# earlgrey register map
Vendor: lowRISC OpenTitan; File version: snapshot-20191101-1-518-g9293d546-dirty
CPU: RISCV 0, little endian, MPU, no FPU, 0 interrupt priority bits
Registers are 32-bit, read-write, reset 0x0 unless marked. A register's access mark holds for its fields unless they carry their own. Offsets are from the block's base; [hi:lo] are bit positions; lines under a group give offsets from that group; {n}, {i} and the like mark numbered series.

## hmac
Base 0x40120000
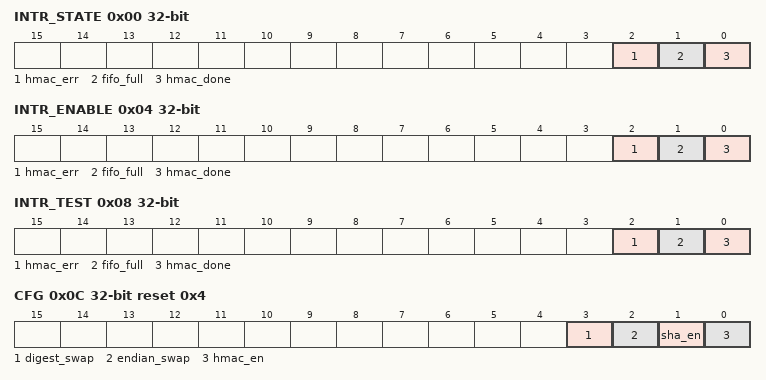
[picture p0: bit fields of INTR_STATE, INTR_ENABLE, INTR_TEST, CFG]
0x00 INTR_STATE — Interrupt State Register
  [2] hmac_err write-1-clears — HMAC error occurred. ERR_CODE register shows which error occurred
  [1] fifo_full write-1-clears — Message FIFO full condition
  [0] hmac_done write-1-clears — HMAC-256 completes a message with key
0x04 INTR_ENABLE — Interrupt Enable Register
  [2] hmac_err — Enable interrupt when !!INTR_STATE.hmac_err is set
  [1] fifo_full — Enable interrupt when !!INTR_STATE.fifo_full is set
  [0] hmac_done — Enable interrupt when !!INTR_STATE.hmac_done is set
0x08 INTR_TEST wo — Interrupt Test Register
  [2] hmac_err — Write 1 to force !!INTR_STATE.hmac_err to 1
  [1] fifo_full — Write 1 to force !!INTR_STATE.fifo_full to 1
  [0] hmac_done — Write 1 to force !!INTR_STATE.hmac_done to 1
0x0C CFG reset 0x4 — HMAC Configuration register. The register is updated when the engine is in Idle. If the software updates the register while the engine computes the hash, the updated value is discarded.
  [3] digest_swap — DIGEST register byte-order. If 1, it swaps each DIGEST registers' byte-order.
  [2] endian_swap — Convert TL-UL wdata[31:0] to big-endian style {w[7:0], w[15:8], .. }
  [1] sha_en — SHA256 enable. If 0, SHA engine won't initiate compression, this is used to stop operation of the SHA engine until configuration has been done. When the SHA engine is disabled the digest is cleared.
  [0] hmac_en — HMAC datapath enable. If this bit is 1, HMAC operates when `hash_start` toggles.
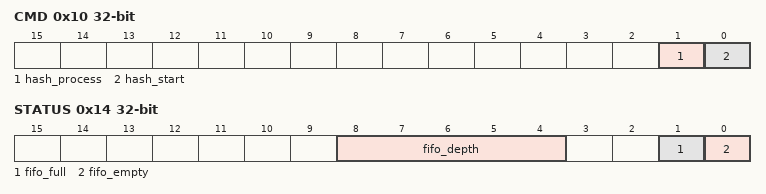
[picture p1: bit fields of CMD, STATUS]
0x10 CMD wo write-1-clears — HMAC command register
  [1] hash_process write-1-clears — If writes 1 into this field, SHA256 or HMAC calculates the digest or signing based on currently received message.
  [0] hash_start write-1-clears — If writes 1 into this field, SHA256 or HMAC begins its operation. CPU should configure relative information first, such as message_length, secret_key.
0x14 STATUS ro — HMAC Status register
  [8:4] fifo_depth — FIFO entry count.
  [1] fifo_full — FIFO full. Data written to the FIFO whilst it is full will cause back-pressure on the interconnect
  [0] fifo_empty
0x18 ERR_CODE ro — HMAC Error Code
  [31:0] err_code — If error interrupt occurs, this register has information of error cause. Please take a look at `hw/ip/hmac/rtl/hmac_pkg.sv:err_code_e enum type.
0x1C WIPE_SECRET wo reset not defined — Randomize internal secret registers. If CPU writes value into the register, the value is used to randomize internal variables such as secret key, internal state machine, or hash value.
  [31:0] secret — Secret value
0x20 KEY group — HMAC Secret Key SHA256 assumes secret key is hashed 256bit key. Order of the secret key is: key[255:0] = {KEY0, KEY1, KEY2, ... , KEY7}; The registers are allowed to be updated when the engine is in Idle state. If the engine computes the hash, it discards any attempts to update the secret keys and report an error.
  0x00 KEY0 wo reset not defined — HMAC Secret Key SHA256 assumes secret key is hashed 256bit key. Order of the secret key is: key[255:0] = {KEY0, KEY1, KEY2, ... , KEY7}; The registers are allowed to be updated when the engine is in Idle state. If the engine computes the hash, it discards any attempts to update the secret keys and report an error.
    [31:0] key0 — 32-bit chunk of 256-bit Secret Key for HMAC0
  0x04 KEY1 wo reset not defined — HMAC Secret Key SHA256 assumes secret key is hashed 256bit key. Order of the secret key is: key[255:0] = {KEY0, KEY1, KEY2, ... , KEY7}; The registers are allowed to be updated when the engine is in Idle state. If the engine computes the hash, it discards any attempts to update the secret keys and report an error.
    [31:0] key1 — 32-bit chunk of 256-bit Secret Key for HMAC1
  0x08 KEY2 wo reset not defined — HMAC Secret Key SHA256 assumes secret key is hashed 256bit key. Order of the secret key is: key[255:0] = {KEY0, KEY1, KEY2, ... , KEY7}; The registers are allowed to be updated when the engine is in Idle state. If the engine computes the hash, it discards any attempts to update the secret keys and report an error.
    [31:0] key2 — 32-bit chunk of 256-bit Secret Key for HMAC2
  0x0C KEY3 wo reset not defined — HMAC Secret Key SHA256 assumes secret key is hashed 256bit key. Order of the secret key is: key[255:0] = {KEY0, KEY1, KEY2, ... , KEY7}; The registers are allowed to be updated when the engine is in Idle state. If the engine computes the hash, it discards any attempts to update the secret keys and report an error.
    [31:0] key3 — 32-bit chunk of 256-bit Secret Key for HMAC3
  0x10 KEY4 wo reset not defined — HMAC Secret Key SHA256 assumes secret key is hashed 256bit key. Order of the secret key is: key[255:0] = {KEY0, KEY1, KEY2, ... , KEY7}; The registers are allowed to be updated when the engine is in Idle state. If the engine computes the hash, it discards any attempts to update the secret keys and report an error.
    [31:0] key4 — 32-bit chunk of 256-bit Secret Key for HMAC4
  0x14 KEY5 wo reset not defined — HMAC Secret Key SHA256 assumes secret key is hashed 256bit key. Order of the secret key is: key[255:0] = {KEY0, KEY1, KEY2, ... , KEY7}; The registers are allowed to be updated when the engine is in Idle state. If the engine computes the hash, it discards any attempts to update the secret keys and report an error.
    [31:0] key5 — 32-bit chunk of 256-bit Secret Key for HMAC5
  0x18 KEY6 wo reset not defined — HMAC Secret Key SHA256 assumes secret key is hashed 256bit key. Order of the secret key is: key[255:0] = {KEY0, KEY1, KEY2, ... , KEY7}; The registers are allowed to be updated when the engine is in Idle state. If the engine computes the hash, it discards any attempts to update the secret keys and report an error.
    [31:0] key6 — 32-bit chunk of 256-bit Secret Key for HMAC6
  0x1C KEY7 wo reset not defined — HMAC Secret Key SHA256 assumes secret key is hashed 256bit key. Order of the secret key is: key[255:0] = {KEY0, KEY1, KEY2, ... , KEY7}; The registers are allowed to be updated when the engine is in Idle state. If the engine computes the hash, it discards any attempts to update the secret keys and report an error.
    [31:0] key7 — 32-bit chunk of 256-bit Secret Key for HMAC7
0x40 DIGEST group — Digest output. If HMAC is disabled, the register shows result of SHA256 Order of the digest is: digest[255:0] = {DIGEST0, DIGEST1, DIGEST2, ... , DIGEST7};
  0x00 DIGEST0 ro — Digest output. If HMAC is disabled, the register shows result of SHA256 Order of the digest is: digest[255:0] = {DIGEST0, DIGEST1, DIGEST2, ... , DIGEST7};
    [31:0] digest0 — 32-bit chunk of 256-bit Digest for HMAC0
  0x04 DIGEST1 ro — Digest output. If HMAC is disabled, the register shows result of SHA256 Order of the digest is: digest[255:0] = {DIGEST0, DIGEST1, DIGEST2, ... , DIGEST7};
    [31:0] digest1 — 32-bit chunk of 256-bit Digest for HMAC1
  0x08 DIGEST2 ro — Digest output. If HMAC is disabled, the register shows result of SHA256 Order of the digest is: digest[255:0] = {DIGEST0, DIGEST1, DIGEST2, ... , DIGEST7};
    [31:0] digest2 — 32-bit chunk of 256-bit Digest for HMAC2
  0x0C DIGEST3 ro — Digest output. If HMAC is disabled, the register shows result of SHA256 Order of the digest is: digest[255:0] = {DIGEST0, DIGEST1, DIGEST2, ... , DIGEST7};
    [31:0] digest3 — 32-bit chunk of 256-bit Digest for HMAC3
  0x10 DIGEST4 ro — Digest output. If HMAC is disabled, the register shows result of SHA256 Order of the digest is: digest[255:0] = {DIGEST0, DIGEST1, DIGEST2, ... , DIGEST7};
    [31:0] digest4 — 32-bit chunk of 256-bit Digest for HMAC4
  0x14 DIGEST5 ro — Digest output. If HMAC is disabled, the register shows result of SHA256 Order of the digest is: digest[255:0] = {DIGEST0, DIGEST1, DIGEST2, ... , DIGEST7};
    [31:0] digest5 — 32-bit chunk of 256-bit Digest for HMAC5
  0x18 DIGEST6 ro — Digest output. If HMAC is disabled, the register shows result of SHA256 Order of the digest is: digest[255:0] = {DIGEST0, DIGEST1, DIGEST2, ... , DIGEST7};
    [31:0] digest6 — 32-bit chunk of 256-bit Digest for HMAC6
  0x1C DIGEST7 ro — Digest output. If HMAC is disabled, the register shows result of SHA256 Order of the digest is: digest[255:0] = {DIGEST0, DIGEST1, DIGEST2, ... , DIGEST7};
    [31:0] digest7 — 32-bit chunk of 256-bit Digest for HMAC7
0x60 MSG_LENGTH_LOWER ro — Received Message Length calculated by the HMAC in bits [31:0] Message is byte granularity. lower 3bits [2:0] are ignored.
  [31:0] v — Message Length [31:0]
0x64 MSG_LENGTH_UPPER ro — Received Message Length calculated by the HMAC in bits [63:32]
  [31:0] v — Message Length [63:32]
{0x800+4i} MSG_FIFO{i} (i=0..511) wo reset not defined — Message FIFO. Any write to this window will be appended to the FIFO. Only the lower [1:0] bits of the address matter to writes within the window (for correctly dealing with non 32-bit writes)
